# MSPM0G351X register map
Vendor: Texas Instruments; File version: This preliminary header file does not have a version number - build date: 2024-07-25 04:30:36
CPU: CM0 r0p1, little endian, MPU, no FPU, 3 interrupt priority bits
Registers are 32-bit, read-write, reset 0x0 unless marked. A register's access mark holds for its fields unless they carry their own. Offsets are from the block's base; [hi:lo] are bit positions; {n}, {i} and the like mark numbered series.

## CANFD0 (part 3 of 3) — PERIPHERALREGION
Base 0x40508000
0x6800 CANFD0_PWREN — Power enable
  [0] ENABLE — Enable the power
    0=DISABLE (Disable Power); 1=ENABLE (Enable Power)
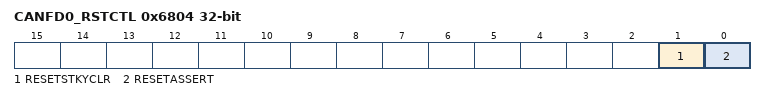
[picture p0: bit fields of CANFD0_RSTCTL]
0x6804 CANFD0_RSTCTL wo — Reset Control
  [1] RESETSTKYCLR — Clear the RESETSTKY bit in the STAT register
    0=NOP (Writing 0 has no effect); 1=CLR (Clear reset sticky bit)
  [0] RESETASSERT — Assert reset to the peripheral
    0=NOP (Writing 0 has no effect); 1=ASSERT (Assert reset)
0x6814 CANFD0_STAT ro — Status Register
  [16] RESETSTKY — This bit indicates, if the peripheral was reset, since this bit was cleared by RESETSTKYCLR in the RSTCTL register
    0=NORES (The peripheral has not been reset since this bit was last cleared by RESETSTKYCLR in the RSTCTL register); 1=RESET (The peripheral was reset since the last bit clear)

## CANFD1 (part 3 of 3) — PERIPHERALREGION
Base 0x40510000
Registers as CANFD0 (with CANFD0 read as CANFD1).

## KEYSTORECTL — PERIPHERALREGION
Base 0x400AC000
0x1100 KEYSTORECTL_CFG reset 0x1 — Keystore configuration
  [3:0] NK256 — Number of 256 bit keys to be held in the key-store. Can not exceed the total number of slots present in the hardware / 2. For eg: if SYS_N_SLOTS = 4, then atmost 2 256-bit keys can be held in the key-store. Incorrect setting of this field will be reported via STATUS register
    0=ZERO (No 256-bit keys); 1=ONE (One 256-bit key); 2=TWO (Two 256-bit keys); 3=THREE (Three 256-bit keys); 4=FOUR (Four 256-bit keys)
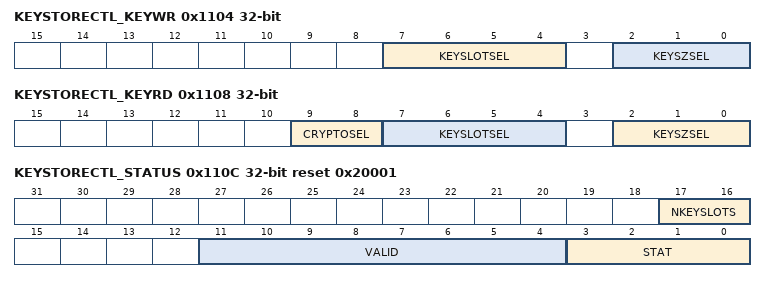
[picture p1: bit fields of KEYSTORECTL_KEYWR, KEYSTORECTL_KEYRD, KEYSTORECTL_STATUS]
0x1104 KEYSTORECTL_KEYWR — Key write configuration
  [7:4] KEYSLOTSEL — Select the key slot to write the key into. NOTE: SW needs to ensure that it is writing to the correct slots. The slot numbering is from 0 through SYS_N_SLOTS-1. Each slot is a 128-bit slot. Therefore, when writing a 256-bit key, two slots will need to budgeted. The selected slot for the 256-bit key needs to be an even numbered slot (eg: 0 or 2). Also all the 256-bit keys need to be stored in lower numbered slots and 128-bit keys stored in higher numbered slots.
    {v}=SLOT{v} (v=0..7)
  [2:0] KEYSZSEL — Key size selection. Selection of 128 or 256 bit keys
    0=K256 (256 bit key); 1=K128 (128 bit key)
0x1108 KEYSTORECTL_KEYRD — Key read configuration
  [9:8] CRYPTOSEL — Crypto engine selector
    0=AES (Transfer key to AES)
  [7:4] KEYSLOTSEL — Select the key slot to read the key from. NOTE: SW needs to ensure that it is reading from the correct slots. The slot numbering is from 0 through SYS_N_SLOTS-1. Each slot is a 128-bit slot. Therefore, when reading a 256-bit key, two adjacent slots will be read. For a 256-bit key, an even numbered slot index must be specified.
  [2:0] KEYSZSEL — Key size selection. Selection of 128 or 256 bit keys
    0=K256 (256 bit key); 1=K128 (128 bit key)
0x110C KEYSTORECTL_STATUS ro reset 0x20001 — Status
  [17:16] NKEYSLOTS — Size of keystorage: Number of 128-bit key slots
    0=TWO (Two slots); 1=THREE (Three slots); 2=FOUR (Four slots)
  [11:4] VALID — Bitvector of valid bits to indicate which slots have been configured
  [3:0] STAT — Status information
    0=VALID (Valid configuration); 1=NO_CFG (Key-store has not been configured. NK256 has not been set.); 2=INVALID_NK256 (Invalid value for NK256 field in CFG.); 3=BUSY_RECEIVE (Busy receiving a key deposit); 4=BUSY_TRANSMIT (Busy transmitting a key to a crypto engine); 5=INVALID_KEYSLOTSELW (Invalid keyslot selection for writing); 6=INVALID_KEYSLOTSELR (Invalid keyslot selection for reading)
0x1110 KEYSTORECTL_KEYIN wo — Input key
0x1114 KEYSTORECTL_KEYLOCK — Keylock
  [7:0] LOCKBIT — Bitvector of lock bits to lock certain slots from being used by application.

## ADC0_SVT — PERIPHERALREGIONSVT
Base 0x40556000
0x556160 ADC0_SVT_FIFODATA ro — FIFO Data Register
{0x556280+4i} ADC0_SVT_MEMRES[{i}] (i=0..23) ro — Memory Result Register
  [15:0] DATA — MEMRES result register. If DF = 0, unsigned binary: The conversion results are right aligned. In 10 and 8 bit modes, the unused MSB bits are forced to 0. If DF = 1, 2s-complement format: The conversion results are left aligned. In 10 and 8 bit modes, the unused LSB bits are forced to 0. The data is stored in the right-justified format and is converted to the left-justified 2s-complement format during read back.

## ADC1_SVT — PERIPHERALREGIONSVT
Base 0x40558000
Registers as ADC0_SVT (with ADC0_SVT read as ADC1_SVT).
